# AST1060 register map
File version: 1.0
CPU: CM4 r0p1, little endian, MPU, FPU, 4 interrupt priority bits, 256 interrupts
Registers are 32-bit, read-write, reset 0x0 unless marked. A register's access mark holds for its fields unless they carry their own. Offsets are from the block's base; [hi:lo] are bit positions; {n}, {i} and the like mark numbered series; 'fields as' and 'values as' point back to an identical list.

## fmc
Base 0x7E620000
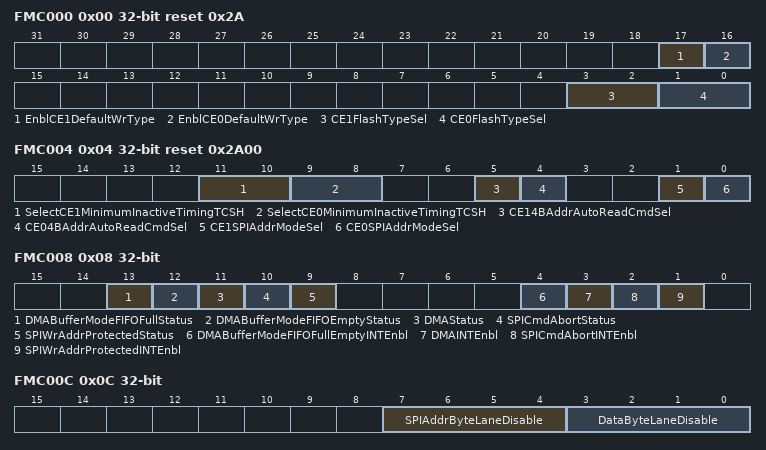
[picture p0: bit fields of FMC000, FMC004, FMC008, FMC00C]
0x00 FMC000 reset 0x2A — CE Type Setting Register
  [17] EnblCE1DefaultWrType — Enable CE1 default write type
  [16] EnblCE0DefaultWrType — Enable CE0 default write type
    0=CEx_Is_Default_At_Write_Disable_Mode; 1=CEx_Is_Default_At_Write_Enable_Mode
  [3:2] CE1FlashTypeSel ro — CE1 flash type selection
  [1:0] CE0FlashTypeSel ro — CE0 flash type selection
    2=Select_SPI_Flash_Type
0x04 FMC004 reset 0x2A00 — CE Control Register
  [11:10] SelectCE1MinimumInactiveTimingTCSH
  [9:8] SelectCE0MinimumInactiveTimingTCSH
    0=16_X_HCLK; 1=24_X_HCLK; 2=32_X_HCLK; 3=40_X_HCLK
  [5] CE14BAddrAutoReadCmdSel — CE1 4B address Auto-Read command selection
  [4] CE04BAddrAutoReadCmdSel — CE0 4B address Auto-Read command selection
    0=Use_0x03_Command; 1=Use_0x13_Command
  [1] CE1SPIAddrModeSel — CE1 SPI address mode selection
  [0] CE0SPIAddrModeSel — CE0 SPI address mode selection
    0=3B3_Bytes_Smaller_Than_Or_Equal_To_16MB; 1=4B4_Bytes_Larger_Than_16MB
0x08 FMC008 — Interrupt Control and Status Register
  [13] DMABufferModeFIFOFullStatus ro
    0=FIFO_Is_Nonfull; 1=FIFO_Is_Full
  [12] DMABufferModeFIFOEmptyStatus ro
    0=FIFO_Is_Nonempty; 1=FIFO_Is_Empty
  [11] DMAStatus ro
    0=Busy_When_DMA_Was_Enabled_Or_Idle_When_DMA_Was_Disabled; 1=DMA_Finish
  [10] SPICmdAbortStatus — SPI Command Abort Status
  [9] SPIWrAddrProtectedStatus — SPI Write Address Protected Status
  [4] DMABufferModeFIFOFullEmptyINTEnbl — DMA Buffer Mode FIFO Full/Empty Interrupt Enable
  [3] DMAINTEnbl — DMA Interrupt Enable
  [2] SPICmdAbortINTEnbl — SPI Command Abort Interrupt Enable
  [1] SPIWrAddrProtectedINTEnbl — SPI Write Address Protected Interrupt Enable
    0=Disable; 1=Enable
0x0C FMC00C — Command Control Register
  [7:4] SPIAddrByteLaneDisable — SPI Address Byte lane disable
    0bxxx1=Disable_Address_Byte_0; 0bxx1x=Disable_Address_Byte_1; 0bx1xx=Disable_Address_Byte_2; 0b1xxx=Disable_Address_Byte_3_Only_Valid_For_4byte_Address_Mode
  [3:0] DataByteLaneDisable
    0bxxx1=Disable_Data_Byte_0; 0bxx1x=Disable_Data_Byte_1; 0bx1xx=Disable_Data_Byte_2; 0b1xxx=Disable_Data_Byte_3
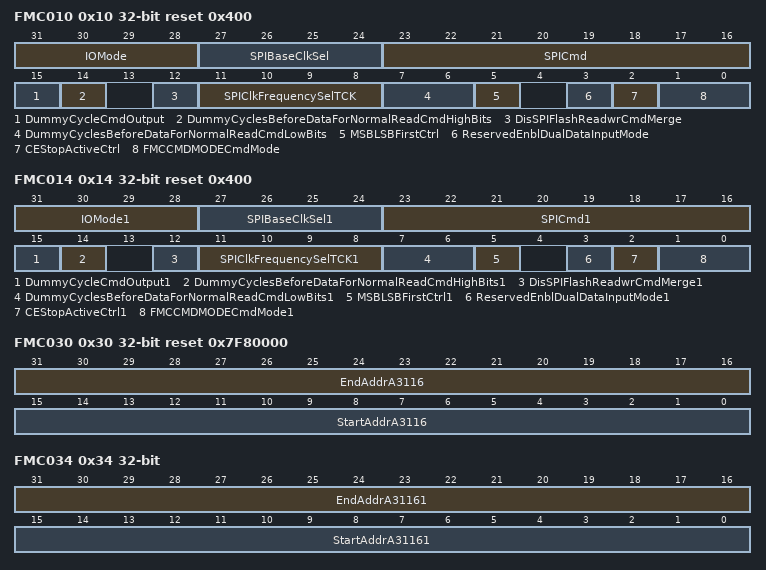
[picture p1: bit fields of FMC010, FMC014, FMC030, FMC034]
0x10 FMC010 reset 0x400 (reset mask 0xFFFFDFE7) — SPI CE0 Control Register
  [31:28] IOMode
    0=Single_Bit; 2=Dual_Bit_Readwrite_Data_Cycle_Only; 3=Dual_Bit_Readwrite_Including_Address_And_Dummy_Byte_Cycle; 4=Quad_Bit_Readwrite_Data_Cycle_Only; 5=Quad_Bit_Readwrite_Including_Address_And_Dummy_Byte_Cycle; 0b1xxx=QPI_Mode_Quad_Bit_On_Commandaddressdata_Cycles
  [27:24] SPIBaseClkSel — SPI base clock selection
    0=Baseclk__0___HCLK; 1=Baseclk__16__HCLK; 2=Baseclk__32__HCLK; 3=Baseclk__48__HCLK; 15=Baseclk__240__HCLK
  [23:16] SPICmd — SPI Command
  [15] DummyCycleCmdOutput — Dummy cycle command output
    0=Dummy_Cycle_No_Command_Output; 1=First_Dummy_Cycle_Has_Command_Output
  [14] DummyCyclesBeforeDataForNormalReadCmdHighBits — Dummy cycles before data for Normal-Read command (high bits)
  [12] DisSPIFlashReadwrCmdMerge — Disable SPI flash read/write command merge
    0=Enable; 1=Disable_With_Performance_Penalty
  [11:8] SPIClkFrequencySelTCK — SPI clock frequency selection (t-CK)
    0=Baseclk__16__HCLK; 1=Baseclk__14__HCLK; 2=Baseclk__12__HCLK; 3=Baseclk__10__HCLK; 4=Baseclk__8__HCLKregdefmark (baseclk + (~8 * HCLK) egdefmark); 5=Baseclk__6__HCLK; 6=Baseclk__4__HCLK; 7=Baseclk__2__HCLK; 8=Baseclk__15__HCLK; 9=Baseclk__13__HCLK; 10=Baseclk__11__HCLK; 11=Baseclk__9__HCLK; 12=Baseclk__7__HCLK; 13=Baseclk__5__HCLK; 14=Baseclk__3__HCLK; 15=Baseclk__1__HCLK_Only_Valid_For_Baseclk_Selection_Not_Equal_To_0
  [7:6] DummyCyclesBeforeDataForNormalReadCmdLowBits — Dummy cycles before data for Normal-Read command (low bits)
  [5] MSBLSBFirstCtrl — MSB/LSB first control
    0=MSB_First_HtextAdefault_For_Boot_Code; 1=LSB_First
  [3] ReservedEnblDualDataInputMode — Reserved Enable dual data input mode
    0=28__010_Mode
  [2] CEStopActiveCtrl — CE# Stop Active Control
  [1:0] FMCCMDMODECmdMode — FMCCMDMODECommand Mode
    0=AutoRead_0x030x13__Address__Read_Data_1234_Bytes; 1=NormalRead_CMD__Address__Read_Data_1234_Bytes; 2=NormalWrite_CMD__Address__Write_Data_1234_Bytes; 3=UserMode_Readwrite_Data_1234_Bytes
0x14 FMC014 reset 0x400 (reset mask 0xFFFFDFE7) — SPI CE1 Control Register
  [31:28] IOMode1 — IO Mode
    values as FMC010.IOMode
  [27:24] SPIBaseClkSel1 — SPI base clock selection
    values as FMC010.SPIBaseClkSel
  [23:16] SPICmd1 — SPI Command
  [15] DummyCycleCmdOutput1 — Dummy cycle command output
    values as FMC010.DummyCycleCmdOutput
  [14] DummyCyclesBeforeDataForNormalReadCmdHighBits1 — Dummy cycles before data for Normal-Read command (high bits)
  [12] DisSPIFlashReadwrCmdMerge1 — Disable SPI flash read/write command merge
    0=Enable; 1=Disable_With_Performance_Penalty
  [11:8] SPIClkFrequencySelTCK1 — SPI clock frequency selection (t-CK)
    values as FMC010.SPIClkFrequencySelTCK
  [7:6] DummyCyclesBeforeDataForNormalReadCmdLowBits1 — Dummy cycles before data for Normal-Read command (low bits)
  [5] MSBLSBFirstCtrl1 — MSB/LSB first control
    0=MSB_First_HtextAdefault_For_Boot_Code; 1=LSB_First
  [3] ReservedEnblDualDataInputMode1 — Reserved Enable dual data input mode
    0=28__010_Mode
  [2] CEStopActiveCtrl1 — CE# Stop Active Control
  [1:0] FMCCMDMODECmdMode1 — FMCCMDMODECommand Mode
    values as FMC010.FMCCMDMODECmdMode
0x30 FMC030 reset 0x7F80000 — CE0 Address Decoding Range Register
  [31:16] EndAddrA3116 — End address A[31:16]
  [15:0] StartAddrA3116 — Start address A[31:16]
0x34 FMC034 — CE1 Address Decoding Range Register
  [31:16] EndAddrA31161 — End address A[31:16]
  [15:0] StartAddrA31161 — Start address A[31:16]
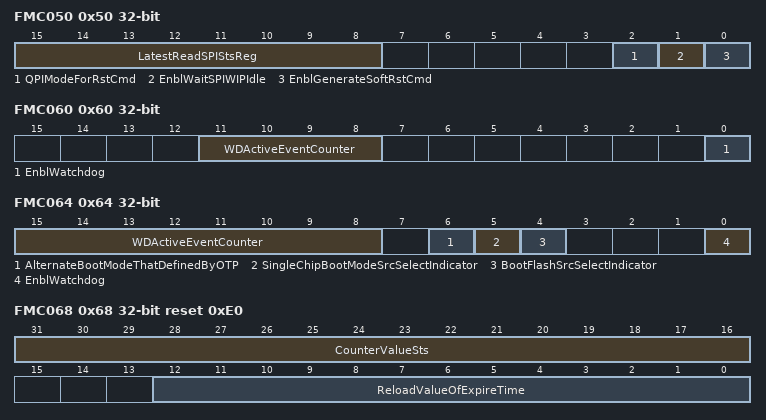
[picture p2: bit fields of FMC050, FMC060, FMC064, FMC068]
0x50 FMC050 — Auto Soft-Reset Command Control
  [15:8] LatestReadSPIStsReg ro — Latest read SPI status register
  [2] QPIModeForRstCmd ro — QPI mode for reset command
  [1] EnblWaitSPIWIPIdle — Enable wait SPI WIP idle
  [0] EnblGenerateSoftRstCmd — Enable generate soft-reset command
0x54 FMC054 — SPI Dummy Cycle Data Register
  [7:0] SPIDummyCycleOutputData
0x60 FMC060 — FMC\_WDT1 Control/Status Register for Address Mode Detection
  [11:8] WDActiveEventCounter ro — Watchdog active event counter
  [0] EnblWatchdog — Enable watchdog
0x64 FMC064 — FMC\_WDT2 Control/Status Register for Alternate Boot
  [15:8] WDActiveEventCounter ro — Watchdog active event counter
  [6] AlternateBootModeThatDefinedByOTP ro
    0=2_Chips_Mode; 1=1_Chip_Mode
  [5] SingleChipBootModeSrcSelectIndicator ro — Single chip boot mode source select indicator
  [4] BootFlashSrcSelectIndicator — Boot flash source select indicator
    0=Boot_From_Primary_Source; 1=Boot_From_Alternate_Source
  [0] EnblWatchdog — Enable watchdog
0x68 FMC068 reset 0xE0 — FMC\_WDT2 Timer Reload Value Register
  [31:16] CounterValueSts ro — Counter value status
  [12:0] ReloadValueOfExpireTime
0x6C FMC06C — FMC\_WDT2 Timer Restart Register
  [15:0] RestartReg — Restart register
0x7C FMC07C — DMA Buffer Mode Length Register
  [6:0] FIFOLengthStatus
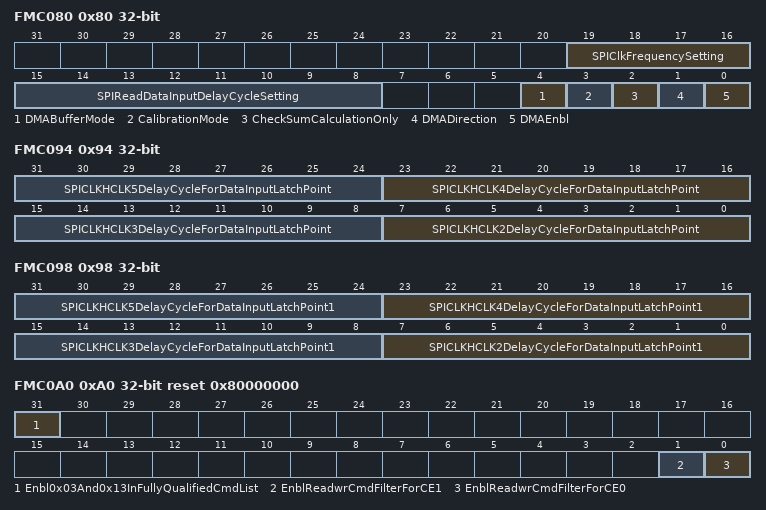
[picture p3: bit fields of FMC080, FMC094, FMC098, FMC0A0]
0x80 FMC080 — DMA Control/Status Register
  [19:16] SPIClkFrequencySetting — SPI clock frequency setting
  [15:8] SPIReadDataInputDelayCycleSetting
  [4] DMABufferMode
    0=Memory_Mode_Transfer_Tofrom_DRAMSRAM; 1=Buffer_Mode_Transfer_Tofrom_DMA_Buffer_The_DMA_Buffer_Works_As_FIFO_Mode_For_Data_Transfer_And_DMA_Will_Stop_Temporarily_When_FIFO_Is_Empty_Or_Full
  [3] CalibrationMode
    0=Normal_Mode; 1=Calibration_Mode_At_This_Mode_SPI_Clock_Rate_And_Read_Delay_Cycle_Parameters
  [2] CheckSumCalculationOnly
    0=Normal_DMA_Operation; 1=Checksum_Accumulation_Only
  [1] DMADirection
    0=Read_Flash_Move_From_Flash_To_External_Memory; 1=Write_Flash_Move_From_External_Memory_To_Flash
  [0] DMAEnbl — DMA Enable
    0=Disable; 1=Enable_DMA_Operation
0x84 FMC084 — DMA Flash Side Address
  [27:2] FlashSideStartAddr — Flash side start address
0x88 FMC088 — DMA DRAM/SRAM Side Address
  [31:2] DRAMSideStartAddrMemoryModeOnly — DRAM side start address (Memory mode only)
0x8C FMC08C — DMA Length Register
  [24:0] DMALength
0x90 FMC090 — CheckSum Calculation Result
  [31:0] CheckSumCalculationResult ro
0x94 FMC094 — CE0 SPI Flash Read Timing Compensation
  [8n-9:8n-16] SPICLKHCLK{n}DelayCycleForDataInputLatchPoint (n=2..5)
0x98 FMC098 — CE1 SPI Flash Read Timing Compensation
  [8n-9:8n-16] SPICLKHCLK{n}DelayCycleForDataInputLatchPoint1 (n=2..5) — SPICLK = HCLK/{n}, delay cycle for data input latch point
0xA0 FMC0A0 reset 0x80000000 — Command Filter Control Register
  [31] Enbl0x03And0x13InFullyQualifiedCmdList — Enable 0x03 and 0x13 in Fully Qualified Command list
  [1] EnblReadwrCmdFilterForCE1 — Enable read/write command filter for CE1
  [0] EnblReadwrCmdFilterForCE0 — Enable read/write command filter for CE0
    0=Disable_Filter_All_Commands_Are_Allowed; 1=Enable_Filter_Only_Commands_Defined_In_HlinkFMC100_Sim_HlinkFMC17C_Are_Allowed
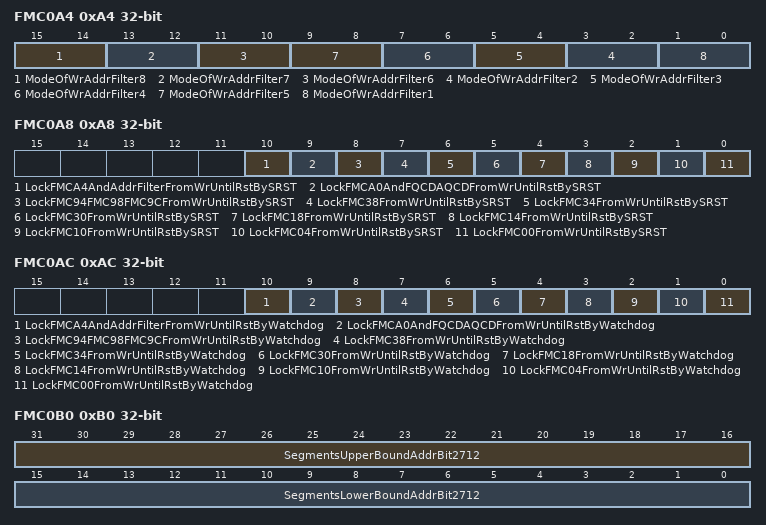
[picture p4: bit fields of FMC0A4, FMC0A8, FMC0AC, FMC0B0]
0xA4 FMC0A4 — Write Address Filter Control Register
  [15:14] ModeOfWrAddrFilter8 — Mode of write address filter \#8
  [13:12] ModeOfWrAddrFilter7 — Mode of write address filter \#7
  [11:10] ModeOfWrAddrFilter6 — Mode of write address filter \#6
  [2n-1:2n-2] ModeOfWrAddrFilter{n} (n=2..5) — Mode of write address filter #{n}
  [1:0] ModeOfWrAddrFilter1 — Mode of write address filter #1
    0=NOP; 1=Read_Only; 2=Write_Only; 3=Access_Disabled
0xA8 FMC0A8 — Register Lock Control Register (SRST\#)
  [10] LockFMCA4AndAddrFilterFromWrUntilRstBySRST — Lock FMCA4 and Address Filter from write until reset by SRST#
  [9] LockFMCA0AndFQCDAQCDFromWrUntilRstBySRST — Lock FMCA0 and FQCD/AQCD from write until reset by SRST#
  [8] LockFMC94FMC98FMC9CFromWrUntilRstBySRST — Lock FMC94/FMC98/FMC9C from write until reset by SRST#
  [7] LockFMC38FromWrUntilRstBySRST — Lock FMC38 from write until reset by SRST#
  [6] LockFMC34FromWrUntilRstBySRST — Lock FMC34 from write until reset by SRST#
  [5] LockFMC30FromWrUntilRstBySRST — Lock FMC30 from write until reset by SRST#
  [4] LockFMC18FromWrUntilRstBySRST — Lock FMC18 from write until reset by SRST#
  [3] LockFMC14FromWrUntilRstBySRST — Lock FMC14 from write until reset by SRST#
  [2] LockFMC10FromWrUntilRstBySRST — Lock FMC10 from write until reset by SRST#
  [1] LockFMC04FromWrUntilRstBySRST — Lock FMC04 from write until reset by SRST#
  [0] LockFMC00FromWrUntilRstBySRST — Lock FMC00 from write until reset by SRST#
0xAC FMC0AC — Register Lock Control Register (Watchdog)
  [10] LockFMCA4AndAddrFilterFromWrUntilRstByWatchdog — Lock FMCA4 and Address Filter from write until reset by watchdog
  [9] LockFMCA0AndFQCDAQCDFromWrUntilRstByWatchdog — Lock FMCA0 and FQCD/AQCD from write until reset by watchdog
  [8] LockFMC94FMC98FMC9CFromWrUntilRstByWatchdog — Lock FMC94/FMC98/FMC9C from write until reset by watchdog
  [7] LockFMC38FromWrUntilRstByWatchdog — Lock FMC38 from write until reset by watchdog
  [6] LockFMC34FromWrUntilRstByWatchdog — Lock FMC34 from write until reset by watchdog
  [5] LockFMC30FromWrUntilRstByWatchdog — Lock FMC30 from write until reset by watchdog
  [4] LockFMC18FromWrUntilRstByWatchdog — Lock FMC18 from write until reset by watchdog
  [3] LockFMC14FromWrUntilRstByWatchdog — Lock FMC14 from write until reset by watchdog
  [2] LockFMC10FromWrUntilRstByWatchdog — Lock FMC10 from write until reset by watchdog
  [1] LockFMC04FromWrUntilRstByWatchdog — Lock FMC04 from write until reset by watchdog
  [0] LockFMC00FromWrUntilRstByWatchdog — Lock FMC00 from write until reset by watchdog
0xB0 FMC0B0 — Write Address Filter Register \#1
  [31:16] SegmentsUpperBoundAddrBit2712 — Segments Upper bound address bit[27:12]
  [15:0] SegmentsLowerBoundAddrBit2712 — Segments Lower bound address bit[27:12]
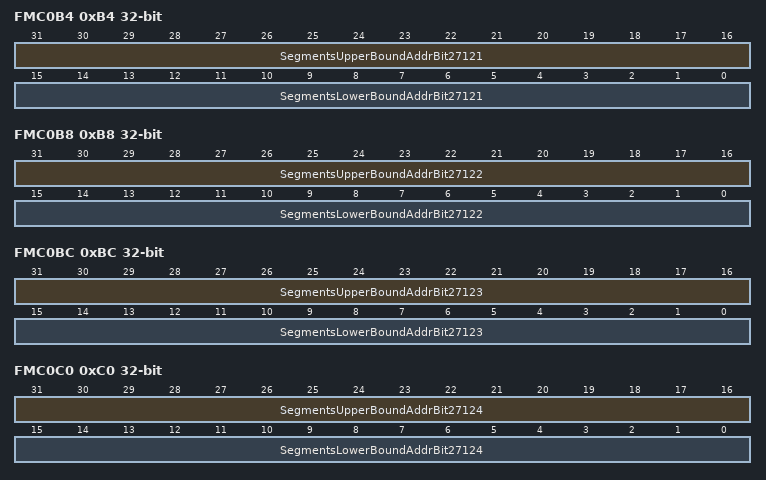
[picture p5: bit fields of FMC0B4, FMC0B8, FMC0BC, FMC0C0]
0xB4 FMC0B4 — Write Address Filter Register \#2
  [31:16] SegmentsUpperBoundAddrBit27121 — Segments Upper bound address bit[27:12]
  [15:0] SegmentsLowerBoundAddrBit27121 — Segments Lower bound address bit[27:12]
0xB8 FMC0B8 — Write Address Filter Register \#3
  [31:16] SegmentsUpperBoundAddrBit27122 — Segments Upper bound address bit[27:12]
  [15:0] SegmentsLowerBoundAddrBit27122 — Segments Lower bound address bit[27:12]
0xBC FMC0BC — Write Address Filter Register \#4
  [31:16] SegmentsUpperBoundAddrBit27123 — Segments Upper bound address bit[27:12]
  [15:0] SegmentsLowerBoundAddrBit27123 — Segments Lower bound address bit[27:12]
0xC0 FMC0C0 — Write Address Filter Register \#5
  [31:16] SegmentsUpperBoundAddrBit27124 — Segments Upper bound address bit[27:12]
  [15:0] SegmentsLowerBoundAddrBit27124 — Segments Lower bound address bit[27:12]
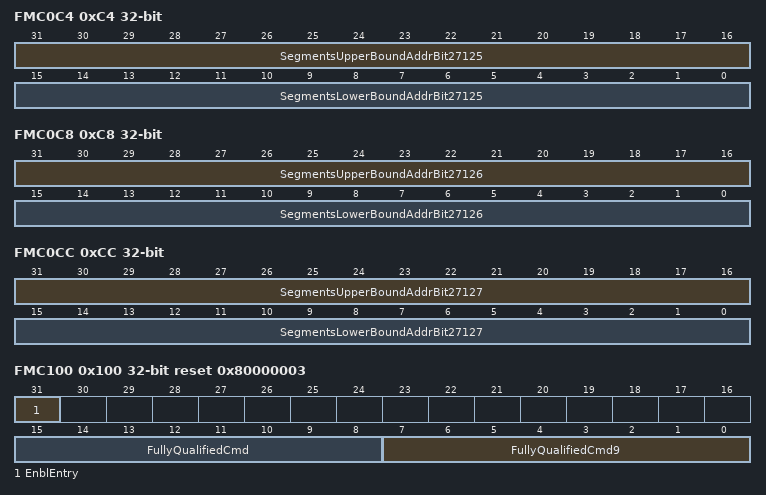
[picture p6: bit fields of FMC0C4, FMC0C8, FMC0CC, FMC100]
0xC4 FMC0C4 — Write Address Filter Register \#6
  [31:16] SegmentsUpperBoundAddrBit27125 — Segments Upper bound address bit[27:12]
  [15:0] SegmentsLowerBoundAddrBit27125 — Segments Lower bound address bit[27:12]
0xC8 FMC0C8 — Write Address Filter Register \#7
  [31:16] SegmentsUpperBoundAddrBit27126 — Segments Upper bound address bit[27:12]
  [15:0] SegmentsLowerBoundAddrBit27126 — Segments Lower bound address bit[27:12]
0xCC FMC0CC — Write Address Filter Register \#8
  [31:16] SegmentsUpperBoundAddrBit27127 — Segments Upper bound address bit[27:12]
  [15:0] SegmentsLowerBoundAddrBit27127 — Segments Lower bound address bit[27:12]
0x100 FMC100 reset 0x80000003 — Fully Qualified Command
  [31] EnblEntry — Enable Entry
  [15:8] FullyQualifiedCmd — Fully qualified Command
  [7:0] FullyQualifiedCmd9 — Fully qualified Command
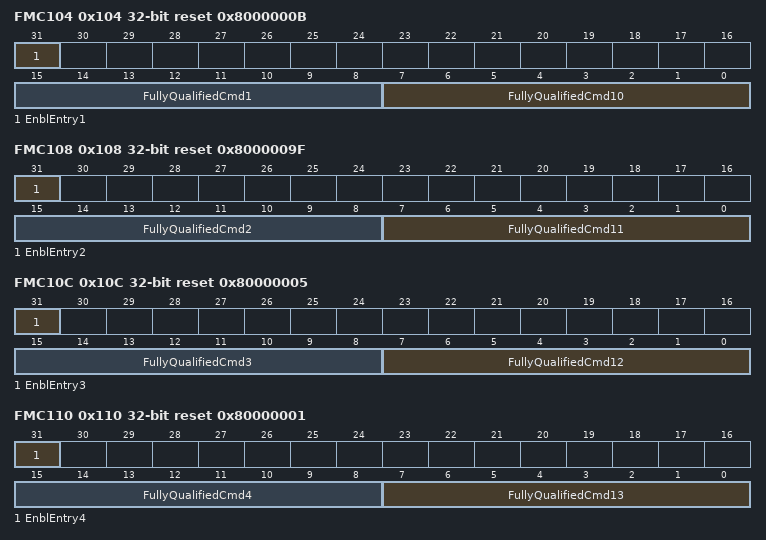
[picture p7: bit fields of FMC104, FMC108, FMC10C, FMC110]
0x104 FMC104 reset 0x8000000B — Fully Qualified Command
  [31] EnblEntry1 — Enable Entry
  [15:8] FullyQualifiedCmd1 — Fully qualified Command
  [7:0] FullyQualifiedCmd10 — Fully qualified Command
0x108 FMC108 reset 0x8000009F — Fully Qualified Command
  [31] EnblEntry2 — Enable Entry
  [15:8] FullyQualifiedCmd2 — Fully qualified Command
  [7:0] FullyQualifiedCmd11 — Fully qualified Command
0x10C FMC10C reset 0x80000005 — Fully Qualified Command
  [31] EnblEntry3 — Enable Entry
  [15:8] FullyQualifiedCmd3 — Fully qualified Command
  [7:0] FullyQualifiedCmd12 — Fully qualified Command
0x110 FMC110 reset 0x80000001 — Fully Qualified Command
  [31] EnblEntry4 — Enable Entry
  [15:8] FullyQualifiedCmd4 — Fully qualified Command
  [7:0] FullyQualifiedCmd13 — Fully qualified Command
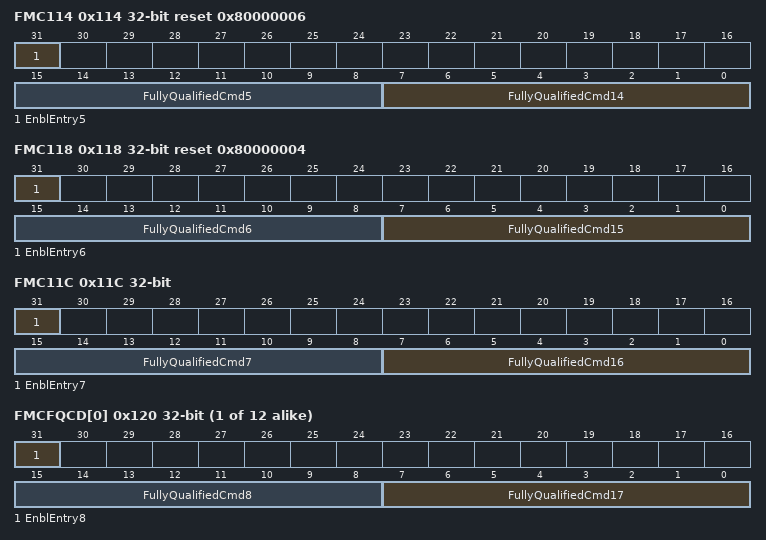
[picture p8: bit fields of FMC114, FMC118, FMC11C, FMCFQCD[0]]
0x114 FMC114 reset 0x80000006 — Fully Qualified Command
  [31] EnblEntry5 — Enable Entry
  [15:8] FullyQualifiedCmd5 — Fully qualified Command
  [7:0] FullyQualifiedCmd14 — Fully qualified Command
0x118 FMC118 reset 0x80000004 — Fully Qualified Command
  [31] EnblEntry6 — Enable Entry
  [15:8] FullyQualifiedCmd6 — Fully qualified Command
  [7:0] FullyQualifiedCmd15 — Fully qualified Command
0x11C FMC11C — Fully Qualified Command
  [31] EnblEntry7 — Enable Entry
  [15:8] FullyQualifiedCmd7 — Fully qualified Command
  [7:0] FullyQualifiedCmd16 — Fully qualified Command
{0x120+4i} FMCFQCD[{i}] (i=0..11) — Fully Qualified Command
  [31] EnblEntry8 — Enable Entry
  [15:8] FullyQualifiedCmd8 — Fully qualified Command
  [7:0] FullyQualifiedCmd17 — Fully qualified Command
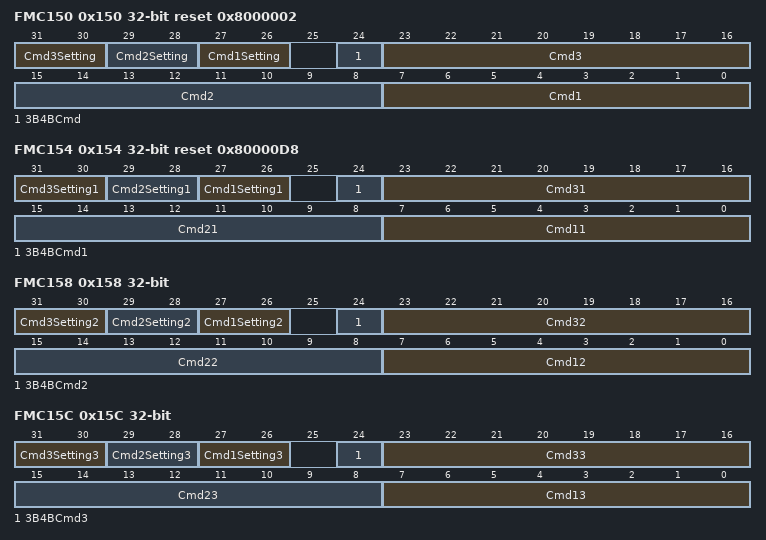
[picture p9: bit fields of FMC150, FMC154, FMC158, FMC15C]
0x150 FMC150 reset 0x8000002 — Address Qualified Command
  [31:30] Cmd3Setting — Command #3 setting
    0=Disable; 1=For_Read; 2=For_Write; 3=For_Read_And_Write
  [29:28] Cmd2Setting — Command #2 setting
    0=Disable; 1=For_Read; 2=For_Write; 3=For_Read_And_Write
  [27:26] Cmd1Setting — Command #1 setting
    0=Disable; 1=For_Read; 2=For_Write; 3=For_Read_And_Write
  [24] 3B4BCmd — 3B/4B Command
    0=Command_321_Are_For_3B_Mode; 1=Command_321_Are_For_4B_Mode
  [23:16] Cmd3 — Command #3
  [15:8] Cmd2 — Command #2
  [7:0] Cmd1 — Command #1
0x154 FMC154 reset 0x80000D8 — Address Qualified Command
  [31:30] Cmd3Setting1 — Command #3 setting
    0=Disable; 1=For_Read; 2=For_Write; 3=For_Read_And_Write
  [29:28] Cmd2Setting1 — Command #2 setting
    0=Disable; 1=For_Read; 2=For_Write; 3=For_Read_And_Write
  [27:26] Cmd1Setting1 — Command #1 setting
    0=Disable; 1=For_Read; 2=For_Write; 3=For_Read_And_Write
  [24] 3B4BCmd1 — 3B/4B Command
    0=Command_321_Are_For_3B_Mode; 1=Command_321_Are_For_4B_Mode
  [23:16] Cmd31 — Command #3
  [15:8] Cmd21 — Command #2
  [7:0] Cmd11 — Command #1
0x158 FMC158 — Address Qualified Command
  [31:30] Cmd3Setting2 — Command #3 setting
    0=Disable; 1=For_Read; 2=For_Write; 3=For_Read_And_Write
  [29:28] Cmd2Setting2 — Command #2 setting
    0=Disable; 1=For_Read; 2=For_Write; 3=For_Read_And_Write
  [27:26] Cmd1Setting2 — Command #1 setting
    0=Disable; 1=For_Read; 2=For_Write; 3=For_Read_And_Write
  [24] 3B4BCmd2 — 3B/4B Command
    0=Command_321_Are_For_3B_Mode; 1=Command_321_Are_For_4B_Mode
  [23:16] Cmd32 — Command #3
  [15:8] Cmd22 — Command #2
  [7:0] Cmd12 — Command #1
0x15C FMC15C — Address Qualified Command
  [31:30] Cmd3Setting3 — Command #3 setting
    0=Disable; 1=For_Read; 2=For_Write; 3=For_Read_And_Write
  [29:28] Cmd2Setting3 — Command #2 setting
    0=Disable; 1=For_Read; 2=For_Write; 3=For_Read_And_Write
  [27:26] Cmd1Setting3 — Command #1 setting
    0=Disable; 1=For_Read; 2=For_Write; 3=For_Read_And_Write
  [24] 3B4BCmd3 — 3B/4B Command
    0=Command_321_Are_For_3B_Mode; 1=Command_321_Are_For_4B_Mode
  [23:16] Cmd33 — Command #3
  [15:8] Cmd23 — Command #2
  [7:0] Cmd13 — Command #1
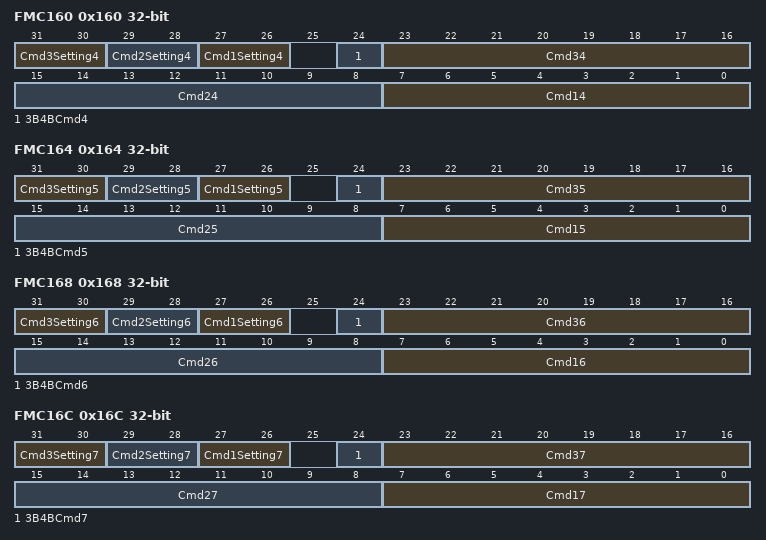
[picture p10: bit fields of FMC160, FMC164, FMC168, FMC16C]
0x160 FMC160 — Address Qualified Command
  [31:30] Cmd3Setting4 — Command #3 setting
    0=Disable; 1=For_Read; 2=For_Write; 3=For_Read_And_Write
  [29:28] Cmd2Setting4 — Command #2 setting
    0=Disable; 1=For_Read; 2=For_Write; 3=For_Read_And_Write
  [27:26] Cmd1Setting4 — Command #1 setting
    0=Disable; 1=For_Read; 2=For_Write; 3=For_Read_And_Write
  [24] 3B4BCmd4 — 3B/4B Command
    0=Command_321_Are_For_3B_Mode; 1=Command_321_Are_For_4B_Mode
  [23:16] Cmd34 — Command #3
  [15:8] Cmd24 — Command #2
  [7:0] Cmd14 — Command #1
0x164 FMC164 — Address Qualified Command
  [31:30] Cmd3Setting5 — Command #3 setting
    0=Disable; 1=For_Read; 2=For_Write; 3=For_Read_And_Write
  [29:28] Cmd2Setting5 — Command #2 setting
    0=Disable; 1=For_Read; 2=For_Write; 3=For_Read_And_Write
  [27:26] Cmd1Setting5 — Command #1 setting
    0=Disable; 1=For_Read; 2=For_Write; 3=For_Read_And_Write
  [24] 3B4BCmd5 — 3B/4B Command
    0=Command_321_Are_For_3B_Mode; 1=Command_321_Are_For_4B_Mode
  [23:16] Cmd35 — Command #3
  [15:8] Cmd25 — Command #2
  [7:0] Cmd15 — Command #1
0x168 FMC168 — Address Qualified Command
  [31:30] Cmd3Setting6 — Command #3 setting
    0=Disable; 1=For_Read; 2=For_Write; 3=For_Read_And_Write
  [29:28] Cmd2Setting6 — Command #2 setting
    0=Disable; 1=For_Read; 2=For_Write; 3=For_Read_And_Write
  [27:26] Cmd1Setting6 — Command #1 setting
    0=Disable; 1=For_Read; 2=For_Write; 3=For_Read_And_Write
  [24] 3B4BCmd6 — 3B/4B Command
    0=Command_321_Are_For_3B_Mode; 1=Command_321_Are_For_4B_Mode
  [23:16] Cmd36 — Command #3
  [15:8] Cmd26 — Command #2
  [7:0] Cmd16 — Command #1
0x16C FMC16C — Address Qualified Command
  [31:30] Cmd3Setting7 — Command #3 setting
    0=Disable; 1=For_Read; 2=For_Write; 3=For_Read_And_Write
  [29:28] Cmd2Setting7 — Command #2 setting
    0=Disable; 1=For_Read; 2=For_Write; 3=For_Read_And_Write
  [27:26] Cmd1Setting7 — Command #1 setting
    0=Disable; 1=For_Read; 2=For_Write; 3=For_Read_And_Write
  [24] 3B4BCmd7 — 3B/4B Command
    0=Command_321_Are_For_3B_Mode; 1=Command_321_Are_For_4B_Mode
  [23:16] Cmd37 — Command #3
  [15:8] Cmd27 — Command #2
  [7:0] Cmd17 — Command #1
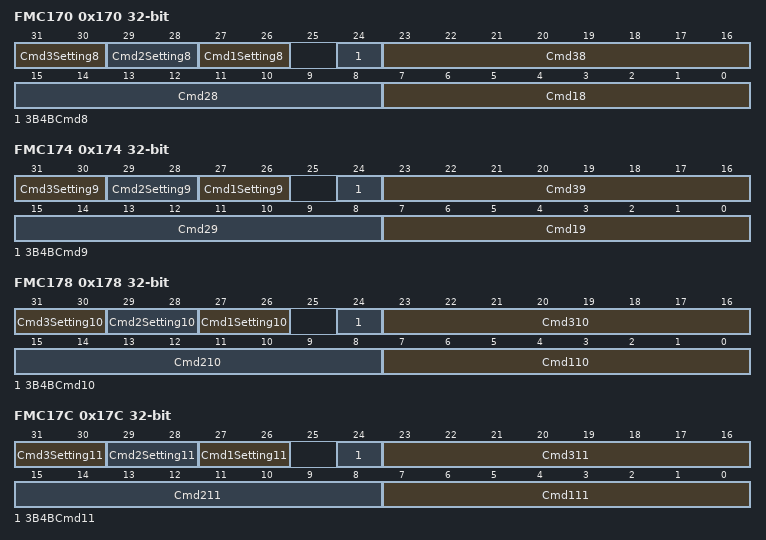
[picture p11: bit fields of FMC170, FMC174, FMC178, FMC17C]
0x170 FMC170 — Address Qualified Command
  [31:30] Cmd3Setting8 — Command #3 setting
    0=Disable; 1=For_Read; 2=For_Write; 3=For_Read_And_Write
  [29:28] Cmd2Setting8 — Command #2 setting
    0=Disable; 1=For_Read; 2=For_Write; 3=For_Read_And_Write
  [27:26] Cmd1Setting8 — Command #1 setting
    0=Disable; 1=For_Read; 2=For_Write; 3=For_Read_And_Write
  [24] 3B4BCmd8 — 3B/4B Command
    0=Command_321_Are_For_3B_Mode; 1=Command_321_Are_For_4B_Mode
  [23:16] Cmd38 — Command #3
  [15:8] Cmd28 — Command #2
  [7:0] Cmd18 — Command #1
0x174 FMC174 — Address Qualified Command
  [31:30] Cmd3Setting9 — Command #3 setting
    0=Disable; 1=For_Read; 2=For_Write; 3=For_Read_And_Write
  [29:28] Cmd2Setting9 — Command #2 setting
    0=Disable; 1=For_Read; 2=For_Write; 3=For_Read_And_Write
  [27:26] Cmd1Setting9 — Command #1 setting
    0=Disable; 1=For_Read; 2=For_Write; 3=For_Read_And_Write
  [24] 3B4BCmd9 — 3B/4B Command
    0=Command_321_Are_For_3B_Mode; 1=Command_321_Are_For_4B_Mode
  [23:16] Cmd39 — Command #3
  [15:8] Cmd29 — Command #2
  [7:0] Cmd19 — Command #1
0x178 FMC178 — Address Qualified Command
  [31:30] Cmd3Setting10 — Command #3 setting
    0=Disable; 1=For_Read; 2=For_Write; 3=For_Read_And_Write
  [29:28] Cmd2Setting10 — Command #2 setting
    0=Disable; 1=For_Read; 2=For_Write; 3=For_Read_And_Write
  [27:26] Cmd1Setting10 — Command #1 setting
    0=Disable; 1=For_Read; 2=For_Write; 3=For_Read_And_Write
  [24] 3B4BCmd10 — 3B/4B Command
    0=Command_321_Are_For_3B_Mode; 1=Command_321_Are_For_4B_Mode
  [23:16] Cmd310 — Command #3
  [15:8] Cmd210 — Command #2
  [7:0] Cmd110 — Command #1
0x17C FMC17C — Address Qualified Command
  [31:30] Cmd3Setting11 — Command #3 setting
    0=Disable; 1=For_Read; 2=For_Write; 3=For_Read_And_Write
  [29:28] Cmd2Setting11 — Command #2 setting
    0=Disable; 1=For_Read; 2=For_Write; 3=For_Read_And_Write
  [27:26] Cmd1Setting11 — Command #1 setting
    0=Disable; 1=For_Read; 2=For_Write; 3=For_Read_And_Write
  [24] 3B4BCmd11 — 3B/4B Command
    0=Command_321_Are_For_3B_Mode; 1=Command_321_Are_For_4B_Mode
  [23:16] Cmd311 — Command #3
  [15:8] Cmd211 — Command #2
  [7:0] Cmd111 — Command #1
{0x200+4i} FMCBUF[{i}] (i=0..63) — DMA Buffer Data Register
  [31:0] DMABufferReadwrPort — DMA Buffer read/write port
